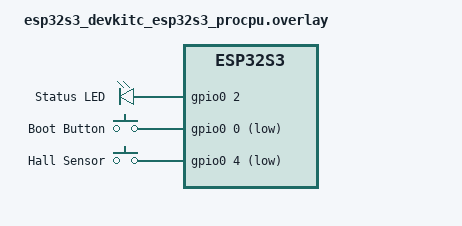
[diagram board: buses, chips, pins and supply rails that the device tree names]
/ {
    /* Define physical GPIO nodes for ESP32-S3 */
    leds {
        compatible = "gpio-leds";
        led0: led_0 {
            gpios = <&gpio0 2 GPIO_ACTIVE_HIGH>; /* Physical onboard LED (e.g., GPIO2) */
            label = "Status LED";
        };
    };

    buttons {
        compatible = "gpio-keys";
        button0: button_0 {
            gpios = <&gpio0 0 (GPIO_PULL_UP | GPIO_ACTIVE_LOW)>; /* Onboard BOOT button (GPIO0) */
            label = "Boot Button";
        };
        button1: button_1 {
            gpios = <&gpio0 4 (GPIO_PULL_UP | GPIO_ACTIVE_LOW)>; /* External pin as Hall sensor (GPIO4) */
            label = "Hall Sensor";
        };
    };

    /* Point aliases to the defined nodes */
    aliases {
        led0 = &led0;
        sw0 = &button0;
        hal0 = &button1;
    };
};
